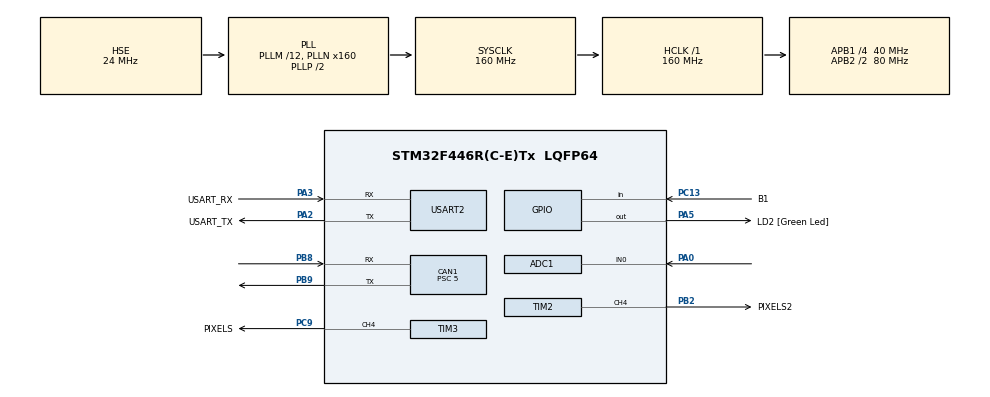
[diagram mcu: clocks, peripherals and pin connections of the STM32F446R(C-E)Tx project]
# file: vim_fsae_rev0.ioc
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ADC1.Channel-0\#ChannelRegularConversion=ADC_CHANNEL_0
ADC1.NbrOfConversionFlag=1
ADC1.Rank-0\#ChannelRegularConversion=1
ADC1.SamplingTime-0\#ChannelRegularConversion=ADC_SAMPLETIME_3CYCLES
ADC1.master=1
CAN1.ABOM=ENABLE
CAN1.AWUM=ENABLE
CAN1.BS1=CAN_BS1_6TQ
CAN1.BS2=CAN_BS2_1TQ
CAN1.CalculateBaudRate=1000000
CAN1.CalculateTimeBit=1000
CAN1.CalculateTimeQuantum=125.0
CAN1.Mode=CAN_MODE_NORMAL
CAN1.Prescaler=5
Dma.Request0=TIM2_UP/CH4
Dma.Request1=TIM3_CH4/UP
Dma.TIM2_UP/CH4.0.Direction=DMA_MEMORY_TO_PERIPH
Dma.TIM2_UP/CH4.0.FIFOMode=DMA_FIFOMODE_DISABLE
Dma.TIM2_UP/CH4.0.Instance=DMA1_Stream7
Dma.TIM2_UP/CH4.0.MemDataAlignment=DMA_MDATAALIGN_HALFWORD
Dma.TIM2_UP/CH4.0.MemInc=DMA_MINC_ENABLE
Dma.TIM2_UP/CH4.0.Mode=DMA_NORMAL
Dma.TIM2_UP/CH4.0.PeriphDataAlignment=DMA_PDATAALIGN_HALFWORD
Dma.TIM2_UP/CH4.0.PeriphInc=DMA_PINC_DISABLE
Dma.TIM2_UP/CH4.0.Priority=DMA_PRIORITY_LOW
Dma.TIM3_CH4/UP.1.Direction=DMA_MEMORY_TO_PERIPH
Dma.TIM3_CH4/UP.1.FIFOMode=DMA_FIFOMODE_DISABLE
Dma.TIM3_CH4/UP.1.Instance=DMA1_Stream2
Dma.TIM3_CH4/UP.1.MemDataAlignment=DMA_MDATAALIGN_HALFWORD
Dma.TIM3_CH4/UP.1.MemInc=DMA_MINC_ENABLE
Dma.TIM3_CH4/UP.1.Mode=DMA_NORMAL
Dma.TIM3_CH4/UP.1.PeriphDataAlignment=DMA_PDATAALIGN_HALFWORD
Dma.TIM3_CH4/UP.1.PeriphInc=DMA_PINC_DISABLE
Dma.TIM3_CH4/UP.1.Priority=DMA_PRIORITY_LOW
FREERTOS.Tasks01=taskMain_Loop,0,256,task_main_loop,Default,NULL,Dynamic,NULL,NULL;taskGCAN_Hardwa,0,256,task_gcan_hw,Default,NULL,Dynamic,NULL,NULL
FREERTOS.configMINIMAL_STACK_SIZE=256
FREERTOS.configUSE_NEWLIB_REENTRANT=1
Mcu.Family=STM32F4
Mcu.Name=STM32F446R(C-E)Tx
Mcu.Package=LQFP64
NVIC.CAN1_RX0_IRQn=true\:5\:0\:false\:false\:true\:true\:true\:true\:true
NVIC.CAN1_RX1_IRQn=true\:5\:0\:false\:false\:true\:true\:true\:true\:true
NVIC.CAN1_TX_IRQn=true\:5\:0\:false\:false\:true\:true\:true\:true\:true
NVIC.DMA1_Stream2_IRQn=true\:5\:0\:false\:false\:true\:true\:false\:true\:true
NVIC.DMA1_Stream7_IRQn=true\:5\:0\:false\:false\:true\:true\:false\:true\:true
NVIC.PriorityGroup=NVIC_PRIORITYGROUP_4
NVIC.TIM6_DAC_IRQn=true\:15\:0\:false\:false\:true\:false\:false\:true\:true
NVIC.TimeBase=TIM6_DAC_IRQn
NVIC.TimeBaseIP=TIM6
PA0-WKUP.Signal=ADCx_IN0
PA2.GPIO_Label=USART_TX
PA2.Mode=Asynchronous
PA2.Signal=USART2_TX
PA3.GPIO_Label=USART_RX
PA3.Mode=Asynchronous
PA3.Signal=USART2_RX
PA5.GPIO_Label=LD2 [Green Led]
PA5.Signal=GPIO_Output
PB2.GPIO_Label=PIXELS2
PB2.Signal=S_TIM2_CH4
PB8.GPIO_PuPd=GPIO_PULLUP
PB8.Mode=CAN_Activate
PB8.Signal=CAN1_RX
PB9.GPIO_PuPd=GPIO_PULLUP
PB9.Mode=CAN_Activate
PB9.Signal=CAN1_TX
PC13.GPIO_Label=B1
PC13.Signal=GPIO_Input
PC9.GPIO_Label=PIXELS
PC9.Signal=S_TIM3_CH4
PH0-OSC_IN.Mode=HSE-External-Clock-Source
PH0-OSC_IN.Signal=RCC_OSC_IN
PH1-OSC_OUT.Mode=HSE-External-Clock-Source
PH1-OSC_OUT.Signal=RCC_OSC_OUT
ProjectManager.HeapSize=0x200
ProjectManager.StackSize=0x400
ProjectManager.TargetToolchain=STM32CubeIDE
RCC.48MHZClocksFreq_Value=84000000
RCC.AHBFreq_Value=160000000
RCC.APB1CLKDivider=RCC_HCLK_DIV4
RCC.APB1Freq_Value=40000000
RCC.APB1TimFreq_Value=80000000
RCC.APB2CLKDivider=RCC_HCLK_DIV2
RCC.APB2Freq_Value=80000000
RCC.APB2TimFreq_Value=160000000
RCC.CortexFreq_Value=160000000
RCC.FLatency-AdvancedSettings=FLASH_LATENCY_5
RCC.HCLKFreq_Value=160000000
RCC.HSE_VALUE=24000000
RCC.HSI_VALUE=16000000
RCC.PLLM=12
RCC.PLLN=160
RCC.PLLSourceVirtual=RCC_PLLSOURCE_HSE
RCC.SYSCLKFreq_VALUE=160000000
RCC.SYSCLKSource=RCC_SYSCLKSOURCE_PLLCLK
RCC.USBFreq_Value=160000000
RCC.VCOOutputFreq_Value=320000000
SH.ADCx_IN0.0=ADC1_IN0,IN0
SH.S_TIM2_CH4.0=TIM2_CH4,PWM Generation4 CH4
SH.S_TIM3_CH4.0=TIM3_CH4,PWM Generation4 CH4
TIM2.Channel-PWM\ Generation4\ CH4=TIM_CHANNEL_4
TIM2.Period=112
TIM3.Channel-PWM\ Generation4\ CH4=TIM_CHANNEL_4
TIM3.Period=112
USART2.VirtualMode=VM_ASYNC
VP_FREERTOS_VS_CMSIS_V1.Mode=CMSIS_V1
VP_SYS_VS_tim6.Mode=TIM6
VP_TIM2_VS_ClockSourceINT.Mode=Internal
VP_TIM3_VS_ClockSourceINT.Mode=Internal
board=NUCLEO-F446RE

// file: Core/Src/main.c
/* USER CODE BEGIN Header */
/**
  ******************************************************************************
  * @file           : main.c
  * @brief          : Main program body
  ******************************************************************************
  * @attention
  *
  * Copyright (c) 2022 STMicroelectronics.
  * All rights reserved.
  *
  * This software is licensed under terms that can be found in the LICENSE file
  * in the root directory of this software component.
  * If no LICENSE file comes with this software, it is provided AS-IS.
  *
  ******************************************************************************
  */
/* USER CODE END Header */
#include "main.h"
#include "cmsis_os.h"

/* USER CODE BEGIN Includes */
#include <stdbool.h>
#include "ledStrip.h"
#include "GopherCAN_Interface.h"

/* USER CODE END Includes */

ADC_HandleTypeDef hadc1;

CAN_HandleTypeDef hcan1;

TIM_HandleTypeDef htim2;
TIM_HandleTypeDef htim3;
DMA_HandleTypeDef hdma_tim2_up_ch4;
DMA_HandleTypeDef hdma_tim3_ch4_up;

UART_HandleTypeDef huart2;

osThreadId taskMain_LoopHandle;
osThreadId taskGCAN_HardwaHandle;

void SystemClock_Config(void);
static void MX_GPIO_Init(void);
static void MX_DMA_Init(void);
static void MX_USART2_UART_Init(void);
static void MX_CAN1_Init(void);
static void MX_TIM2_Init(void);
static void MX_TIM3_Init(void);
static void MX_ADC1_Init(void);
void task_main_loop(void const * argument);
void task_gcan_hw(void const * argument);

/* USER CODE BEGIN 0 */
//bool debounce();
/* USER CODE END 0 */

int main(void)
{

  /* MCU Configuration--------------------------------------------------------*/

  /* Reset of all peripherals, Initializes the Flash interface and the Systick. */
  HAL_Init();

  /* Configure the system clock */
  SystemClock_Config();

  /* Initialize all configured peripherals */
  MX_GPIO_Init();
  MX_DMA_Init();
  MX_USART2_UART_Init();
  MX_CAN1_Init();
  MX_TIM2_Init();
  MX_TIM3_Init();
  MX_ADC1_Init();
  /* USER CODE BEGIN 2 */
  init(&hcan1);
//  clear();
//  setStripBrightness(100);
//  uint16_t i = 0;
//  uint16_t k = 0;
//  uint32_t rpm = 0;
//  uint16_t state = 0;
//  uint32_t lastUpdate = 0;

  /* USER CODE END 2 */

  /* Create the thread(s) */
  /* definition and creation of taskMain_Loop */
  osThreadDef(taskMain_Loop, task_main_loop, osPriorityNormal, 0, 256);
  taskMain_LoopHandle = osThreadCreate(osThread(taskMain_Loop), NULL);

  /* definition and creation of taskGCAN_Hardwa */
  osThreadDef(taskGCAN_Hardwa, task_gcan_hw, osPriorityNormal, 0, 256);
  taskGCAN_HardwaHandle = osThreadCreate(osThread(taskGCAN_Hardwa), NULL);

  /* Start scheduler */
  osKernelStart();

  /* We should never get here as control is now taken by the scheduler */
  /* Infinite loop */
  /* USER CODE BEGIN WHILE */
  while (1)
	{
//	  if(debounce()){
//		  state++;
//		  if(state > 4)
//		  {
//			  state = 0;
//		  }
//	  }
//
//	  uint32_t time = HAL_GetTick();
//
//	  if(state == 0)
//	  {
//		  if(time - lastUpdate >= 10) {
//			  rainbow(i);
//			  write();
//			  i++;
//			  lastUpdate = time;
//			  if(i >= NUM_PIXELS){
//				  i = 0;
//			  }
//		  }
//	  }
//	  else if(state == 1)
//	  {
//
//		  if(time - lastUpdate >= 10)
//		  {
//			  rpm += 5;
//			  lastUpdate = time;
//
//			  if(rpm < 200) {
//				  rainbow(i);
//				  i++;
//				  if(i >= NUM_PIXELS){
//					  i = 0;
//				  }
//			  }
//			  else
//			  {
//				  uint32_t percent = map(rpm, 0, 1000, 0, 100);
//				  drawColorProgressBar(percent, 255, 0, 0, 0, 255, 128);
//			  }
//			  write();
//		  }
//		  if(rpm > 1000)
//		  {
//			  rpm = 0;
//		  }
//	  }
//	  else if(state == 2)
//	  {
//		  if(time - lastUpdate > 5)
//		  {
//			  drawSmoothRainbow(k);
//			  k++;
//			  write();
//			  if(k > 2000)
//			  {
//				  k = 0;
//			  }
//			  lastUpdate = time;
//		  }
//	  }
//	  else
//	  {
//		  clear();
//		  write();
//	  }

    /* USER CODE END WHILE */

  }
}

void SystemClock_Config(void)
{
  RCC_OscInitTypeDef RCC_OscInitStruct = {0};
  RCC_ClkInitTypeDef RCC_ClkInitStruct = {0};

  /** Configure the main internal regulator output voltage
  */
  __HAL_RCC_PWR_CLK_ENABLE();
  __HAL_PWR_VOLTAGESCALING_CONFIG(PWR_REGULATOR_VOLTAGE_SCALE1);

  /** Initializes the RCC Oscillators according to the specified parameters
  * in the RCC_OscInitTypeDef structure.
  */
  RCC_OscInitStruct.OscillatorType = RCC_OSCILLATORTYPE_HSE;
  RCC_OscInitStruct.HSEState = RCC_HSE_BYPASS;
  RCC_OscInitStruct.PLL.PLLState = RCC_PLL_ON;
  RCC_OscInitStruct.PLL.PLLSource = RCC_PLLSOURCE_HSE;
  RCC_OscInitStruct.PLL.PLLM = 12;
  RCC_OscInitStruct.PLL.PLLN = 160;
  RCC_OscInitStruct.PLL.PLLP = RCC_PLLP_DIV2;
  RCC_OscInitStruct.PLL.PLLQ = 2;
  RCC_OscInitStruct.PLL.PLLR = 2;
  if (HAL_RCC_OscConfig(&RCC_OscInitStruct) != HAL_OK)
  {
    Error_Handler();
  }

  /** Initializes the CPU, AHB and APB buses clocks
  */
  RCC_ClkInitStruct.ClockType = RCC_CLOCKTYPE_HCLK|RCC_CLOCKTYPE_SYSCLK
                              |RCC_CLOCKTYPE_PCLK1|RCC_CLOCKTYPE_PCLK2;
  RCC_ClkInitStruct.SYSCLKSource = RCC_SYSCLKSOURCE_PLLCLK;
  RCC_ClkInitStruct.AHBCLKDivider = RCC_SYSCLK_DIV1;
  RCC_ClkInitStruct.APB1CLKDivider = RCC_HCLK_DIV4;
  RCC_ClkInitStruct.APB2CLKDivider = RCC_HCLK_DIV2;

  if (HAL_RCC_ClockConfig(&RCC_ClkInitStruct, FLASH_LATENCY_5) != HAL_OK)
  {
    Error_Handler();
  }
}

static void MX_ADC1_Init(void)
{

  ADC_ChannelConfTypeDef sConfig = {0};

  /** Configure the global features of the ADC (Clock, Resolution, Data Alignment and number of conversion)
  */
  hadc1.Instance = ADC1;
  hadc1.Init.ClockPrescaler = ADC_CLOCK_SYNC_PCLK_DIV4;
  hadc1.Init.Resolution = ADC_RESOLUTION_12B;
  hadc1.Init.ScanConvMode = DISABLE;
  hadc1.Init.ContinuousConvMode = DISABLE;
  hadc1.Init.DiscontinuousConvMode = DISABLE;
  hadc1.Init.ExternalTrigConvEdge = ADC_EXTERNALTRIGCONVEDGE_NONE;
  hadc1.Init.ExternalTrigConv = ADC_SOFTWARE_START;
  hadc1.Init.DataAlign = ADC_DATAALIGN_RIGHT;
  hadc1.Init.NbrOfConversion = 1;
  hadc1.Init.DMAContinuousRequests = DISABLE;
  hadc1.Init.EOCSelection = ADC_EOC_SINGLE_CONV;
  if (HAL_ADC_Init(&hadc1) != HAL_OK)
  {
    Error_Handler();
  }

  /** Configure for the selected ADC regular channel its corresponding rank in the sequencer and its sample time.
  */
  sConfig.Channel = ADC_CHANNEL_0;
  sConfig.Rank = 1;
  sConfig.SamplingTime = ADC_SAMPLETIME_3CYCLES;
  if (HAL_ADC_ConfigChannel(&hadc1, &sConfig) != HAL_OK)
  {
    Error_Handler();
  }

}

static void MX_CAN1_Init(void)
{

  hcan1.Instance = CAN1;
  hcan1.Init.Prescaler = 5;
  hcan1.Init.Mode = CAN_MODE_NORMAL;
  hcan1.Init.SyncJumpWidth = CAN_SJW_1TQ;
  hcan1.Init.TimeSeg1 = CAN_BS1_6TQ;
  hcan1.Init.TimeSeg2 = CAN_BS2_1TQ;
  hcan1.Init.TimeTriggeredMode = DISABLE;
  hcan1.Init.AutoBusOff = ENABLE;
  hcan1.Init.AutoWakeUp = ENABLE;
  hcan1.Init.AutoRetransmission = DISABLE;
  hcan1.Init.ReceiveFifoLocked = DISABLE;
  hcan1.Init.TransmitFifoPriority = DISABLE;
  if (HAL_CAN_Init(&hcan1) != HAL_OK)
  {
    Error_Handler();
  }

}

static void MX_TIM2_Init(void)
{

  TIM_ClockConfigTypeDef sClockSourceConfig = {0};
  TIM_MasterConfigTypeDef sMasterConfig = {0};
  TIM_OC_InitTypeDef sConfigOC = {0};

  htim2.Instance = TIM2;
  htim2.Init.Prescaler = 0;
  htim2.Init.CounterMode = TIM_COUNTERMODE_UP;
  htim2.Init.Period = 112;
  htim2.Init.ClockDivision = TIM_CLOCKDIVISION_DIV1;
  htim2.Init.AutoReloadPreload = TIM_AUTORELOAD_PRELOAD_DISABLE;
  if (HAL_TIM_Base_Init(&htim2) != HAL_OK)
  {
    Error_Handler();
  }
  sClockSourceConfig.ClockSource = TIM_CLOCKSOURCE_INTERNAL;
  if (HAL_TIM_ConfigClockSource(&htim2, &sClockSourceConfig) != HAL_OK)
  {
    Error_Handler();
  }
  if (HAL_TIM_PWM_Init(&htim2) != HAL_OK)
  {
    Error_Handler();
  }
  sMasterConfig.MasterOutputTrigger = TIM_TRGO_RESET;
  sMasterConfig.MasterSlaveMode = TIM_MASTERSLAVEMODE_DISABLE;
  if (HAL_TIMEx_MasterConfigSynchronization(&htim2, &sMasterConfig) != HAL_OK)
  {
    Error_Handler();
  }
  sConfigOC.OCMode = TIM_OCMODE_PWM1;
  sConfigOC.Pulse = 0;
  sConfigOC.OCPolarity = TIM_OCPOLARITY_HIGH;
  sConfigOC.OCFastMode = TIM_OCFAST_DISABLE;
  if (HAL_TIM_PWM_ConfigChannel(&htim2, &sConfigOC, TIM_CHANNEL_4) != HAL_OK)
  {
    Error_Handler();
  }
  HAL_TIM_MspPostInit(&htim2);

}

static void MX_TIM3_Init(void)
{

  TIM_ClockConfigTypeDef sClockSourceConfig = {0};
  TIM_MasterConfigTypeDef sMasterConfig = {0};
  TIM_OC_InitTypeDef sConfigOC = {0};

  htim3.Instance = TIM3;
  htim3.Init.Prescaler = 0;
  htim3.Init.CounterMode = TIM_COUNTERMODE_UP;
  htim3.Init.Period = 112;
  htim3.Init.ClockDivision = TIM_CLOCKDIVISION_DIV1;
  htim3.Init.AutoReloadPreload = TIM_AUTORELOAD_PRELOAD_DISABLE;
  if (HAL_TIM_Base_Init(&htim3) != HAL_OK)
  {
    Error_Handler();
  }
  sClockSourceConfig.ClockSource = TIM_CLOCKSOURCE_INTERNAL;
  if (HAL_TIM_ConfigClockSource(&htim3, &sClockSourceConfig) != HAL_OK)
  {
    Error_Handler();
  }
  if (HAL_TIM_PWM_Init(&htim3) != HAL_OK)
  {
    Error_Handler();
  }
  sMasterConfig.MasterOutputTrigger = TIM_TRGO_RESET;
  sMasterConfig.MasterSlaveMode = TIM_MASTERSLAVEMODE_DISABLE;
  if (HAL_TIMEx_MasterConfigSynchronization(&htim3, &sMasterConfig) != HAL_OK)
  {
    Error_Handler();
  }
  sConfigOC.OCMode = TIM_OCMODE_PWM1;
  sConfigOC.Pulse = 0;
  sConfigOC.OCPolarity = TIM_OCPOLARITY_HIGH;
  sConfigOC.OCFastMode = TIM_OCFAST_DISABLE;
  if (HAL_TIM_PWM_ConfigChannel(&htim3, &sConfigOC, TIM_CHANNEL_4) != HAL_OK)
  {
    Error_Handler();
  }
  HAL_TIM_MspPostInit(&htim3);

}

static void MX_USART2_UART_Init(void)
{

  huart2.Instance = USART2;
  huart2.Init.BaudRate = 115200;
  huart2.Init.WordLength = UART_WORDLENGTH_8B;
  huart2.Init.StopBits = UART_STOPBITS_1;
  huart2.Init.Parity = UART_PARITY_NONE;
  huart2.Init.Mode = UART_MODE_TX_RX;
  huart2.Init.HwFlowCtl = UART_HWCONTROL_NONE;
  huart2.Init.OverSampling = UART_OVERSAMPLING_16;
  if (HAL_UART_Init(&huart2) != HAL_OK)
  {
    Error_Handler();
  }

}

static void MX_DMA_Init(void)
{

  /* DMA controller clock enable */
  __HAL_RCC_DMA1_CLK_ENABLE();

  /* DMA interrupt init */
  /* DMA1_Stream2_IRQn interrupt configuration */
  HAL_NVIC_SetPriority(DMA1_Stream2_IRQn, 5, 0);
  HAL_NVIC_EnableIRQ(DMA1_Stream2_IRQn);
  /* DMA1_Stream7_IRQn interrupt configuration */
  HAL_NVIC_SetPriority(DMA1_Stream7_IRQn, 5, 0);
  HAL_NVIC_EnableIRQ(DMA1_Stream7_IRQn);

}

static void MX_GPIO_Init(void)
{
  GPIO_InitTypeDef GPIO_InitStruct = {0};

  /* GPIO Ports Clock Enable */
  __HAL_RCC_GPIOC_CLK_ENABLE();
  __HAL_RCC_GPIOH_CLK_ENABLE();
  __HAL_RCC_GPIOA_CLK_ENABLE();
  __HAL_RCC_GPIOB_CLK_ENABLE();

  /*Configure GPIO pin Output Level */
  HAL_GPIO_WritePin(LD2_GPIO_Port, LD2_Pin, GPIO_PIN_RESET);

  /*Configure GPIO pin : B1_Pin */
  GPIO_InitStruct.Pin = B1_Pin;
  GPIO_InitStruct.Mode = GPIO_MODE_INPUT;
  GPIO_InitStruct.Pull = GPIO_NOPULL;
  HAL_GPIO_Init(B1_GPIO_Port, &GPIO_InitStruct);

  /*Configure GPIO pin : LD2_Pin */
  GPIO_InitStruct.Pin = LD2_Pin;
  GPIO_InitStruct.Mode = GPIO_MODE_OUTPUT_PP;
  GPIO_InitStruct.Pull = GPIO_NOPULL;
  GPIO_InitStruct.Speed = GPIO_SPEED_FREQ_LOW;
  HAL_GPIO_Init(LD2_GPIO_Port, &GPIO_InitStruct);

}

/* USER CODE BEGIN 4 */
//bool debounce()
//{
//	static uint16_t state = 0;
//	state = (state<<1) | HAL_GPIO_ReadPin(GPIOC, GPIO_PIN_13) | 0xfe00;
//	return (state == 0xff00);
//}
/* USER CODE END 4 */

void task_main_loop(void const * argument)
{
  /* USER CODE BEGIN 5 */
  /* Infinite loop */
  for(;;)
  {
	  main_loop();
    osDelay(10);
  }
  /* USER CODE END 5 */
}

void task_gcan_hw(void const * argument)
{
  /* USER CODE BEGIN task_gcan_hw */
  /* Infinite loop */
  for(;;)
  {
	  can_buffer_handling_loop();
    osDelay(1);
  }
  /* USER CODE END task_gcan_hw */
}

void HAL_TIM_PeriodElapsedCallback(TIM_HandleTypeDef *htim)
{
  if (htim->Instance == TIM6) {
    HAL_IncTick();
  }
}

void Error_Handler(void)
{
  __disable_irq();
  while (1)
  {
  }
}
